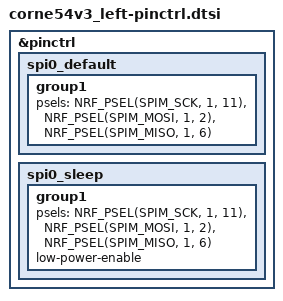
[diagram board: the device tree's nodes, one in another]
/*
 * Copyright (c) 2023 The ZMK Contributors
 * SPDX-License-Identifier: MIT
 */

&pinctrl {
    spi0_default: spi0_default {
        group1 {
            psels = <NRF_PSEL(SPIM_SCK, 1, 11)>,
                <NRF_PSEL(SPIM_MOSI, 1, 2)>,
                <NRF_PSEL(SPIM_MISO, 1, 6)>;
        };
    };
    spi0_sleep: spi0_sleep {
        group1 {
            psels = <NRF_PSEL(SPIM_SCK, 1, 11)>,
                <NRF_PSEL(SPIM_MOSI, 1, 2)>,
                <NRF_PSEL(SPIM_MISO, 1, 6)>;
            low-power-enable;
        };
    };

};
